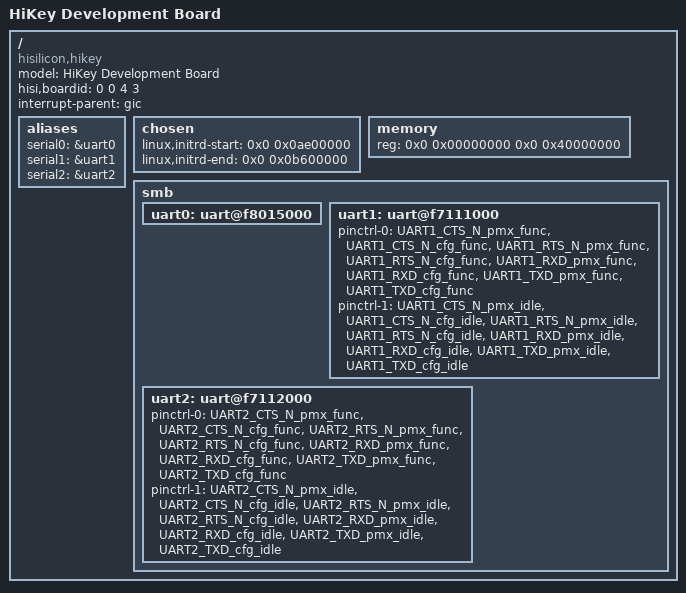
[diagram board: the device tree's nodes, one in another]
/*
 * dts file for Hisilicon HiKey Development Board
 *
 * Copyright (C) 2014, Hisilicon Ltd.
 *
 */

/dts-v1/;

/memreserve/ 0x00000000 0x07400000;
/memreserve/ 0x0740f000 0x1000;

#include "hikey-pinctrl.dtsi"
#include "hi6220.dtsi"

/ {
	model = "HiKey Development Board";
	compatible = "hisilicon,hikey";
	hisi,boardid = <0 0 4 3>;
	#address-cells = <2>;
	#size-cells = <2>;
	interrupt-parent = <&gic>;

	aliases {
		serial0 = &uart0;
		serial1 = &uart1;
		serial2 = &uart2;
	};

	chosen {
		linux,initrd-start = <0x0 0x0ae00000>;
		linux,initrd-end = <0x0 0x0b600000>;
	};

	memory {
		device_type = "memory";
		reg = <0x0 0x00000000 0x0 0x40000000>;
	};

	smb {
		uart0: uart@f8015000 {	/* console */
			status = "ok";
		};

		uart1: uart@f7111000 {
			pinctrl-names = "default", "idle";
			pinctrl-0 = <&UART1_CTS_N_pmx_func
			             &UART1_CTS_N_cfg_func
			             &UART1_RTS_N_pmx_func
				     &UART1_RTS_N_cfg_func
				     &UART1_RXD_pmx_func
				     &UART1_RXD_cfg_func
				     &UART1_TXD_pmx_func
				     &UART1_TXD_cfg_func>;
			pinctrl-1 = <&UART1_CTS_N_pmx_idle
			             &UART1_CTS_N_cfg_idle
			             &UART1_RTS_N_pmx_idle
				     &UART1_RTS_N_cfg_idle
				     &UART1_RXD_pmx_idle
				     &UART1_RXD_cfg_idle
				     &UART1_TXD_pmx_idle
				     &UART1_TXD_cfg_idle>;
			status = "ok";
		};

		uart2: uart@f7112000 {
			pinctrl-names = "default", "idle";
			pinctrl-0 = <&UART2_CTS_N_pmx_func
			             &UART2_CTS_N_cfg_func
			             &UART2_RTS_N_pmx_func
				     &UART2_RTS_N_cfg_func
				     &UART2_RXD_pmx_func
				     &UART2_RXD_cfg_func
				     &UART2_TXD_pmx_func
				     &UART2_TXD_cfg_func>;
			pinctrl-1 = <&UART2_CTS_N_pmx_idle
			             &UART2_CTS_N_cfg_idle
			             &UART2_RTS_N_pmx_idle
				     &UART2_RTS_N_cfg_idle
				     &UART2_RXD_pmx_idle
				     &UART2_RXD_cfg_idle
				     &UART2_TXD_pmx_idle
				     &UART2_TXD_cfg_idle>;
			status = "ok";
		};
	};
};
